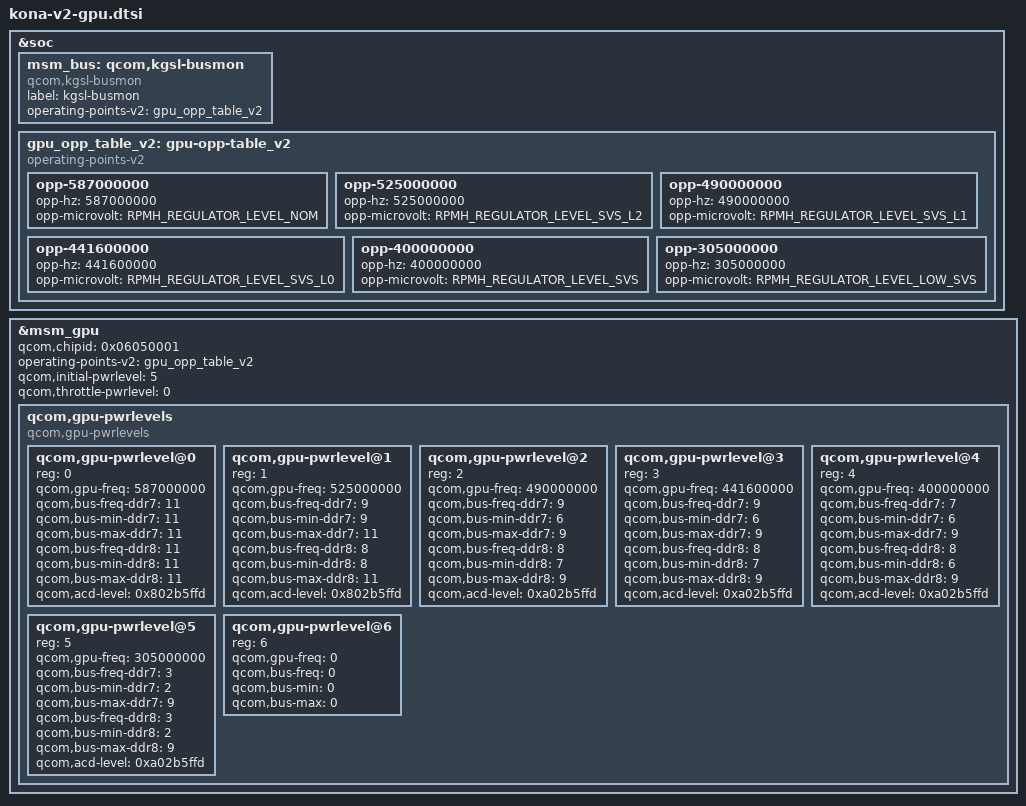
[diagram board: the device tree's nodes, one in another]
&soc {
	msm_bus: qcom,kgsl-busmon {
		label = "kgsl-busmon";
		compatible = "qcom,kgsl-busmon";
		operating-points-v2 = <&gpu_opp_table_v2>;
	};

	gpu_opp_table_v2: gpu-opp-table_v2 {
		compatible = "operating-points-v2";

		opp-587000000 {
			opp-hz = /bits/ 64 <587000000>;
			opp-microvolt = <RPMH_REGULATOR_LEVEL_NOM>;
		};

		opp-525000000 {
			opp-hz = /bits/ 64 <525000000>;
			opp-microvolt = <RPMH_REGULATOR_LEVEL_SVS_L2>;
		};

		opp-490000000 {
			opp-hz = /bits/ 64 <490000000>;
			opp-microvolt = <RPMH_REGULATOR_LEVEL_SVS_L1>;
		};

		opp-441600000 {
			opp-hz = /bits/ 64 <441600000>;
			opp-microvolt = <RPMH_REGULATOR_LEVEL_SVS_L0>;
		};

		opp-400000000 {
			opp-hz = /bits/ 64 <400000000>;
			opp-microvolt = <RPMH_REGULATOR_LEVEL_SVS>;
		};

		opp-305000000 {
			opp-hz = /bits/ 64 <305000000>;
			opp-microvolt = <RPMH_REGULATOR_LEVEL_LOW_SVS>;
		};
	};
};

&msm_gpu {
	qcom,chipid = <0x06050001>;

	/* GPU OPP data */
	operating-points-v2 = <&gpu_opp_table_v2>;

	qcom,initial-pwrlevel = <5>;

	/* Power level to start throttling */
	qcom,throttle-pwrlevel = <0>;

	/* Power levels */
	qcom,gpu-pwrlevels {
		#address-cells = <1>;
		#size-cells = <0>;

		compatible = "qcom,gpu-pwrlevels";

		qcom,gpu-pwrlevel@0 {
			reg = <0>;
			qcom,gpu-freq = <587000000>;
			qcom,bus-freq-ddr7 = <11>;
			qcom,bus-min-ddr7 = <11>;
			qcom,bus-max-ddr7 = <11>;

			qcom,bus-freq-ddr8 = <11>;
			qcom,bus-min-ddr8 = <11>;
			qcom,bus-max-ddr8 = <11>;

			qcom,acd-level = <0x802b5ffd>;
		};

		qcom,gpu-pwrlevel@1 {
			reg = <1>;
			qcom,gpu-freq = <525000000>;
			qcom,bus-freq-ddr7 = <9>;
			qcom,bus-min-ddr7 = <9>;
			qcom,bus-max-ddr7 = <11>;

			qcom,bus-freq-ddr8 = <8>;
			qcom,bus-min-ddr8 = <8>;
			qcom,bus-max-ddr8 = <11>;

			qcom,acd-level = <0x802b5ffd>;
		};

		qcom,gpu-pwrlevel@2 {
			reg = <2>;
			qcom,gpu-freq = <490000000>;
			qcom,bus-freq-ddr7 = <9>;
			qcom,bus-min-ddr7 = <6>;
			qcom,bus-max-ddr7 = <9>;

			qcom,bus-freq-ddr8 = <8>;
			qcom,bus-min-ddr8 = <7>;
			qcom,bus-max-ddr8 = <9>;

			qcom,acd-level = <0xa02b5ffd>;
		};

		qcom,gpu-pwrlevel@3 {
			reg = <3>;
			qcom,gpu-freq = <441600000>;
			qcom,bus-freq-ddr7 = <9>;
			qcom,bus-min-ddr7 = <6>;
			qcom,bus-max-ddr7 = <9>;

			qcom,bus-freq-ddr8 = <8>;
			qcom,bus-min-ddr8 = <7>;
			qcom,bus-max-ddr8 = <9>;

			qcom,acd-level = <0xa02b5ffd>;
		};

		qcom,gpu-pwrlevel@4 {
			reg = <4>;
			qcom,gpu-freq = <400000000>;
			qcom,bus-freq-ddr7 = <7>;
			qcom,bus-min-ddr7 = <6>;
			qcom,bus-max-ddr7 = <9>;

			qcom,bus-freq-ddr8 = <8>;
			qcom,bus-min-ddr8 = <6>;
			qcom,bus-max-ddr8 = <9>;

			qcom,acd-level = <0xa02b5ffd>;
		};

		qcom,gpu-pwrlevel@5 {
			reg = <5>;
			qcom,gpu-freq = <305000000>;
			qcom,bus-freq-ddr7 = <3>;
			qcom,bus-min-ddr7 = <2>;
			qcom,bus-max-ddr7 = <9>;

			qcom,bus-freq-ddr8 = <3>;
			qcom,bus-min-ddr8 = <2>;
			qcom,bus-max-ddr8 = <9>;

			qcom,acd-level = <0xa02b5ffd>;
		};

		qcom,gpu-pwrlevel@6 {
			reg = <6>;
			qcom,gpu-freq = <0>;
			qcom,bus-freq = <0>;
			qcom,bus-min = <0>;
			qcom,bus-max = <0>;
		};
	};
};
